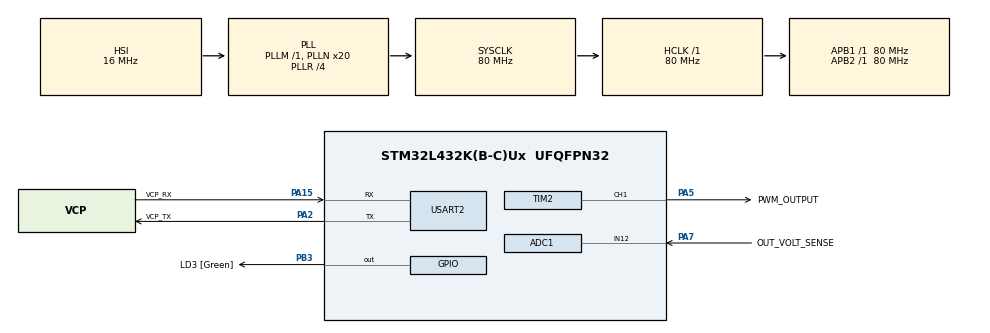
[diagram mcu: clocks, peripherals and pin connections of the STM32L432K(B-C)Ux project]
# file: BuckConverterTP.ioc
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ADC1.Channel-3\#ChannelRegularConversion=ADC_CHANNEL_12
ADC1.ClockPrescaler=ADC_CLOCK_ASYNC_DIV6
ADC1.ContinuousConvMode=ENABLE
ADC1.DMAContinuousRequests=ENABLE
ADC1.NbrOfConversionFlag=1
ADC1.OffsetNumber-3\#ChannelRegularConversion=ADC_OFFSET_NONE
ADC1.Overrun=ADC_OVR_DATA_OVERWRITTEN
ADC1.OversamplingMode=DISABLE
ADC1.Rank-3\#ChannelRegularConversion=1
ADC1.Resolution=ADC_RESOLUTION_12B
ADC1.SamplingTime-3\#ChannelRegularConversion=ADC_SAMPLETIME_640CYCLES_5
ADC1.master=1
Dma.ADC1.0.Direction=DMA_PERIPH_TO_MEMORY
Dma.ADC1.0.Instance=DMA1_Channel1
Dma.ADC1.0.MemDataAlignment=DMA_MDATAALIGN_HALFWORD
Dma.ADC1.0.MemInc=DMA_MINC_ENABLE
Dma.ADC1.0.Mode=DMA_CIRCULAR
Dma.ADC1.0.PeriphDataAlignment=DMA_PDATAALIGN_HALFWORD
Dma.ADC1.0.PeriphInc=DMA_PINC_DISABLE
Dma.ADC1.0.Priority=DMA_PRIORITY_HIGH
Dma.Request0=ADC1
Mcu.Family=STM32L4
Mcu.Name=STM32L432K(B-C)Ux
Mcu.Package=UFQFPN32
NVIC.DMA1_Channel1_IRQn=true\:0\:0\:false\:false\:true\:false\:true\:true
NVIC.PriorityGroup=NVIC_PRIORITYGROUP_4
NVIC.TIM1_BRK_TIM15_IRQn=true\:0\:0\:false\:false\:true\:true\:true\:true
NVIC.TIM1_UP_TIM16_IRQn=true\:0\:0\:false\:false\:true\:true\:true\:true
NVIC.TIM2_IRQn=true\:0\:0\:false\:false\:true\:true\:true\:true
PA0.GPIO_Label=MCO [High speed clock in]
PA0.Mode=HSE-External-Clock-Source-for-LittleOrca
PA0.Signal=RCC_CK_IN
PA13\ (JTMS-SWDIO).GPIO_Label=SWDIO
PA13\ (JTMS-SWDIO).Mode=Serial_Wire
PA13\ (JTMS-SWDIO).Signal=SYS_JTMS-SWDIO
PA14\ (JTCK-SWCLK).GPIO_Label=SWCLK
PA14\ (JTCK-SWCLK).Mode=Serial_Wire
PA14\ (JTCK-SWCLK).Signal=SYS_JTCK-SWCLK
PA15\ (JTDI).GPIO_Label=VCP_RX
PA15\ (JTDI).Mode=Asynchronous
PA15\ (JTDI).Signal=USART2_RX
PA2.GPIO_Label=VCP_TX
PA2.Mode=Asynchronous
PA2.Signal=USART2_TX
PA5.GPIO_Label=PWM_OUTPUT
PA5.GPIO_PuPd=GPIO_NOPULL
PA5.GPIO_Speed=GPIO_SPEED_FREQ_MEDIUM
PA5.Signal=S_TIM2_CH1
PA7.GPIO_Label=OUT_VOLT_SENSE
PA7.Signal=ADCx_IN12
PB3\ (JTDO-TRACESWO).GPIO_Label=LD3 [Green]
PB3\ (JTDO-TRACESWO).Signal=GPIO_Output
PC14-OSC32_IN\ (PC14).Mode=LSE-External-Oscillator
PC14-OSC32_IN\ (PC14).Signal=RCC_OSC32_IN
PC15-OSC32_OUT\ (PC15).Mode=LSE-External-Oscillator
PC15-OSC32_OUT\ (PC15).Signal=RCC_OSC32_OUT
ProjectManager.HeapSize=0x200
ProjectManager.StackSize=0x400
ProjectManager.TargetToolchain=STM32CubeIDE
RCC.ADCFreq_Value=64000000
RCC.AHBFreq_Value=80000000
RCC.APB1Freq_Value=80000000
RCC.APB1TimFreq_Value=80000000
RCC.APB2Freq_Value=80000000
RCC.APB2TimFreq_Value=80000000
RCC.CortexFreq_Value=80000000
RCC.HCLKFreq_Value=80000000
RCC.HSE_VALUE=8000000
RCC.HSI16_VALUE=16000000
RCC.HSI48_VALUE=48000000
RCC.HSI_VALUE=16000000
RCC.MSI_VALUE=4000000
RCC.PLLMUL=RCC_PLLMUL_4
RCC.PLLN=20
RCC.PLLR=RCC_PLLR_DIV4
RCC.PLLSourceVirtual=RCC_PLLSOURCE_HSI
RCC.SYSCLKFreq_VALUE=80000000
RCC.SYSCLKSource=RCC_SYSCLKSOURCE_PLLCLK
RCC.USBFreq_Value=64000000
RCC.VCOOutputFreq_Value=320000000
SH.ADCx_IN12.0=ADC1_IN12,IN12-Single-Ended
SH.S_TIM2_CH1.0=TIM2_CH1,PWM Generation1 CH1
TIM1.Channel-Output\ Compare2\ No\ Output=TIM_CHANNEL_2
TIM1.Period=1000-1
TIM1.Prescaler=16-1
TIM2.Channel-PWM\ Generation1\ CH1=TIM_CHANNEL_1
TIM2.OCMode_PWM-PWM\ Generation1\ CH1=TIM_OCMODE_PWM2
TIM2.Period=1000-1
TIM2.Prescaler=16-1
USART2.VirtualMode-Asynchronous=VM_ASYNC
VP_TIM1_VS_no_output2.Mode=Output Compare2 No Output
board=NUCLEO-L432KC

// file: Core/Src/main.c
/* USER CODE BEGIN Header */
/**
  ******************************************************************************
  * @file           : main.c
  * @brief          : Main program body
  ******************************************************************************
  * @attention
  *
  * Copyright (c) 2024 STMicroelectronics.
  * All rights reserved.
  *
  * This software is licensed under terms that can be found in the LICENSE file
  * in the root directory of this software component.
  * If no LICENSE file comes with this software, it is provided AS-IS.
  *
  ******************************************************************************
  */
/* USER CODE END Header */
#include "main.h"

/* USER CODE BEGIN Includes */
#include "BuckRegulatorMicrocontroller.h"
/* USER CODE END Includes */

ADC_HandleTypeDef hadc1;
DMA_HandleTypeDef hdma_adc1;

TIM_HandleTypeDef htim1;
TIM_HandleTypeDef htim2;

UART_HandleTypeDef huart2;

void SystemClock_Config(void);
static void MX_GPIO_Init(void);
static void MX_DMA_Init(void);
static void MX_USART2_UART_Init(void);
static void MX_ADC1_Init(void);
static void MX_TIM2_Init(void);
static void MX_TIM1_Init(void);

int main(void)
{

  /* MCU Configuration--------------------------------------------------------*/

  /* Reset of all peripherals, Initializes the Flash interface and the Systick. */
  HAL_Init();

  /* USER CODE BEGIN Init */
  BuckRegulatorMicrocontroller_initialize();
  /* USER CODE END Init */

  /* Configure the system clock */
  SystemClock_Config();

  /* Initialize all configured peripherals */
  MX_GPIO_Init();
  MX_DMA_Init();
  MX_USART2_UART_Init();
  MX_ADC1_Init();
  MX_TIM2_Init();
  MX_TIM1_Init();
  /* USER CODE BEGIN 2 */
  rtU.targetVoltage = 5.00;
  uint16_t rawAdcVal = 0;
  rtU.outputVoltage = 0.00;
  // HAL_DMA_Init(&hdma_adc1);
  HAL_TIM_PWM_Start(&htim2, TIM_CHANNEL_1);
  HAL_ADC_Start_DMA(&hadc1, &rawAdcVal, 1);
  /* USER CODE END 2 */

  /* Infinite loop */
  /* USER CODE BEGIN WHILE */
  while (1)
  {
//	  rtU.outputVoltage = rawAdcVal / 297.0; // Voltage divider ratio 20k top 6.8k bottom
//	  BuckRegulatorMicrocontroller_step();
//	  __HAL_TIM_SET_COMPARE(&htim2, TIM_CHANNEL_1, rtY.pwmPercent * 1000); // PWM gets inverted by external BJT
    /* USER CODE END WHILE */

  }
}

void SystemClock_Config(void)
{
  RCC_OscInitTypeDef RCC_OscInitStruct = {0};
  RCC_ClkInitTypeDef RCC_ClkInitStruct = {0};

  /** Configure the main internal regulator output voltage
  */
  if (HAL_PWREx_ControlVoltageScaling(PWR_REGULATOR_VOLTAGE_SCALE1) != HAL_OK)
  {
    Error_Handler();
  }

  /** Initializes the RCC Oscillators according to the specified parameters
  * in the RCC_OscInitTypeDef structure.
  */
  RCC_OscInitStruct.OscillatorType = RCC_OSCILLATORTYPE_HSI;
  RCC_OscInitStruct.HSIState = RCC_HSI_ON;
  RCC_OscInitStruct.HSICalibrationValue = RCC_HSICALIBRATION_DEFAULT;
  RCC_OscInitStruct.PLL.PLLState = RCC_PLL_ON;
  RCC_OscInitStruct.PLL.PLLSource = RCC_PLLSOURCE_HSI;
  RCC_OscInitStruct.PLL.PLLM = 1;
  RCC_OscInitStruct.PLL.PLLN = 20;
  RCC_OscInitStruct.PLL.PLLP = RCC_PLLP_DIV7;
  RCC_OscInitStruct.PLL.PLLQ = RCC_PLLQ_DIV2;
  RCC_OscInitStruct.PLL.PLLR = RCC_PLLR_DIV4;
  if (HAL_RCC_OscConfig(&RCC_OscInitStruct) != HAL_OK)
  {
    Error_Handler();
  }

  /** Initializes the CPU, AHB and APB buses clocks
  */
  RCC_ClkInitStruct.ClockType = RCC_CLOCKTYPE_HCLK|RCC_CLOCKTYPE_SYSCLK
                              |RCC_CLOCKTYPE_PCLK1|RCC_CLOCKTYPE_PCLK2;
  RCC_ClkInitStruct.SYSCLKSource = RCC_SYSCLKSOURCE_PLLCLK;
  RCC_ClkInitStruct.AHBCLKDivider = RCC_SYSCLK_DIV1;
  RCC_ClkInitStruct.APB1CLKDivider = RCC_HCLK_DIV1;
  RCC_ClkInitStruct.APB2CLKDivider = RCC_HCLK_DIV1;

  if (HAL_RCC_ClockConfig(&RCC_ClkInitStruct, FLASH_LATENCY_4) != HAL_OK)
  {
    Error_Handler();
  }
}

static void MX_ADC1_Init(void)
{

  ADC_ChannelConfTypeDef sConfig = {0};

  /** Common config
  */
  hadc1.Instance = ADC1;
  hadc1.Init.ClockPrescaler = ADC_CLOCK_ASYNC_DIV6;
  hadc1.Init.Resolution = ADC_RESOLUTION_12B;
  hadc1.Init.DataAlign = ADC_DATAALIGN_RIGHT;
  hadc1.Init.ScanConvMode = ADC_SCAN_DISABLE;
  hadc1.Init.EOCSelection = ADC_EOC_SINGLE_CONV;
  hadc1.Init.LowPowerAutoWait = DISABLE;
  hadc1.Init.ContinuousConvMode = ENABLE;
  hadc1.Init.NbrOfConversion = 1;
  hadc1.Init.DiscontinuousConvMode = DISABLE;
  hadc1.Init.ExternalTrigConv = ADC_SOFTWARE_START;
  hadc1.Init.ExternalTrigConvEdge = ADC_EXTERNALTRIGCONVEDGE_NONE;
  hadc1.Init.DMAContinuousRequests = ENABLE;
  hadc1.Init.Overrun = ADC_OVR_DATA_OVERWRITTEN;
  hadc1.Init.OversamplingMode = DISABLE;
  if (HAL_ADC_Init(&hadc1) != HAL_OK)
  {
    Error_Handler();
  }

  /** Configure Regular Channel
  */
  sConfig.Channel = ADC_CHANNEL_12;
  sConfig.Rank = ADC_REGULAR_RANK_1;
  sConfig.SamplingTime = ADC_SAMPLETIME_640CYCLES_5;
  sConfig.SingleDiff = ADC_SINGLE_ENDED;
  sConfig.OffsetNumber = ADC_OFFSET_NONE;
  sConfig.Offset = 0;
  if (HAL_ADC_ConfigChannel(&hadc1, &sConfig) != HAL_OK)
  {
    Error_Handler();
  }

}

static void MX_TIM1_Init(void)
{

  TIM_MasterConfigTypeDef sMasterConfig = {0};
  TIM_OC_InitTypeDef sConfigOC = {0};
  TIM_BreakDeadTimeConfigTypeDef sBreakDeadTimeConfig = {0};

  htim1.Instance = TIM1;
  htim1.Init.Prescaler = 16-1;
  htim1.Init.CounterMode = TIM_COUNTERMODE_UP;
  htim1.Init.Period = 1000-1;
  htim1.Init.ClockDivision = TIM_CLOCKDIVISION_DIV1;
  htim1.Init.RepetitionCounter = 0;
  htim1.Init.AutoReloadPreload = TIM_AUTORELOAD_PRELOAD_DISABLE;
  if (HAL_TIM_OC_Init(&htim1) != HAL_OK)
  {
    Error_Handler();
  }
  sMasterConfig.MasterOutputTrigger = TIM_TRGO_RESET;
  sMasterConfig.MasterOutputTrigger2 = TIM_TRGO2_RESET;
  sMasterConfig.MasterSlaveMode = TIM_MASTERSLAVEMODE_DISABLE;
  if (HAL_TIMEx_MasterConfigSynchronization(&htim1, &sMasterConfig) != HAL_OK)
  {
    Error_Handler();
  }
  sConfigOC.OCMode = TIM_OCMODE_TIMING;
  sConfigOC.Pulse = 0;
  sConfigOC.OCPolarity = TIM_OCPOLARITY_HIGH;
  sConfigOC.OCNPolarity = TIM_OCNPOLARITY_HIGH;
  sConfigOC.OCFastMode = TIM_OCFAST_DISABLE;
  sConfigOC.OCIdleState = TIM_OCIDLESTATE_RESET;
  sConfigOC.OCNIdleState = TIM_OCNIDLESTATE_RESET;
  if (HAL_TIM_OC_ConfigChannel(&htim1, &sConfigOC, TIM_CHANNEL_2) != HAL_OK)
  {
    Error_Handler();
  }
  sBreakDeadTimeConfig.OffStateRunMode = TIM_OSSR_DISABLE;
  sBreakDeadTimeConfig.OffStateIDLEMode = TIM_OSSI_DISABLE;
  sBreakDeadTimeConfig.LockLevel = TIM_LOCKLEVEL_OFF;
  sBreakDeadTimeConfig.DeadTime = 0;
  sBreakDeadTimeConfig.BreakState = TIM_BREAK_DISABLE;
  sBreakDeadTimeConfig.BreakPolarity = TIM_BREAKPOLARITY_HIGH;
  sBreakDeadTimeConfig.BreakFilter = 0;
  sBreakDeadTimeConfig.Break2State = TIM_BREAK2_DISABLE;
  sBreakDeadTimeConfig.Break2Polarity = TIM_BREAK2POLARITY_HIGH;
  sBreakDeadTimeConfig.Break2Filter = 0;
  sBreakDeadTimeConfig.AutomaticOutput = TIM_AUTOMATICOUTPUT_DISABLE;
  if (HAL_TIMEx_ConfigBreakDeadTime(&htim1, &sBreakDeadTimeConfig) != HAL_OK)
  {
    Error_Handler();
  }

}

static void MX_TIM2_Init(void)
{

  TIM_MasterConfigTypeDef sMasterConfig = {0};
  TIM_OC_InitTypeDef sConfigOC = {0};

  htim2.Instance = TIM2;
  htim2.Init.Prescaler = 16-1;
  htim2.Init.CounterMode = TIM_COUNTERMODE_UP;
  htim2.Init.Period = 1000-1;
  htim2.Init.ClockDivision = TIM_CLOCKDIVISION_DIV1;
  htim2.Init.AutoReloadPreload = TIM_AUTORELOAD_PRELOAD_DISABLE;
  if (HAL_TIM_PWM_Init(&htim2) != HAL_OK)
  {
    Error_Handler();
  }
  sMasterConfig.MasterOutputTrigger = TIM_TRGO_RESET;
  sMasterConfig.MasterSlaveMode = TIM_MASTERSLAVEMODE_DISABLE;
  if (HAL_TIMEx_MasterConfigSynchronization(&htim2, &sMasterConfig) != HAL_OK)
  {
    Error_Handler();
  }
  sConfigOC.OCMode = TIM_OCMODE_PWM2;
  sConfigOC.Pulse = 0;
  sConfigOC.OCPolarity = TIM_OCPOLARITY_HIGH;
  sConfigOC.OCFastMode = TIM_OCFAST_DISABLE;
  if (HAL_TIM_PWM_ConfigChannel(&htim2, &sConfigOC, TIM_CHANNEL_1) != HAL_OK)
  {
    Error_Handler();
  }
  HAL_TIM_MspPostInit(&htim2);

}

static void MX_USART2_UART_Init(void)
{

  huart2.Instance = USART2;
  huart2.Init.BaudRate = 115200;
  huart2.Init.WordLength = UART_WORDLENGTH_8B;
  huart2.Init.StopBits = UART_STOPBITS_1;
  huart2.Init.Parity = UART_PARITY_NONE;
  huart2.Init.Mode = UART_MODE_TX_RX;
  huart2.Init.HwFlowCtl = UART_HWCONTROL_NONE;
  huart2.Init.OverSampling = UART_OVERSAMPLING_16;
  huart2.Init.OneBitSampling = UART_ONE_BIT_SAMPLE_DISABLE;
  huart2.AdvancedInit.AdvFeatureInit = UART_ADVFEATURE_NO_INIT;
  if (HAL_UART_Init(&huart2) != HAL_OK)
  {
    Error_Handler();
  }

}

static void MX_DMA_Init(void)
{

  /* DMA controller clock enable */
  __HAL_RCC_DMA1_CLK_ENABLE();

  /* DMA interrupt init */
  /* DMA1_Channel1_IRQn interrupt configuration */
  HAL_NVIC_SetPriority(DMA1_Channel1_IRQn, 0, 0);
  HAL_NVIC_EnableIRQ(DMA1_Channel1_IRQn);

}

static void MX_GPIO_Init(void)
{
  GPIO_InitTypeDef GPIO_InitStruct = {0};

  /* GPIO Ports Clock Enable */
  __HAL_RCC_GPIOC_CLK_ENABLE();
  __HAL_RCC_GPIOA_CLK_ENABLE();
  __HAL_RCC_GPIOB_CLK_ENABLE();

  /*Configure GPIO pin Output Level */
  HAL_GPIO_WritePin(LD3_GPIO_Port, LD3_Pin, GPIO_PIN_RESET);

  /*Configure GPIO pin : LD3_Pin */
  GPIO_InitStruct.Pin = LD3_Pin;
  GPIO_InitStruct.Mode = GPIO_MODE_OUTPUT_PP;
  GPIO_InitStruct.Pull = GPIO_NOPULL;
  GPIO_InitStruct.Speed = GPIO_SPEED_FREQ_LOW;
  HAL_GPIO_Init(LD3_GPIO_Port, &GPIO_InitStruct);

}

/* USER CODE BEGIN 4 */
void HAL_TIM_PeriodElapsedCallback(TIM_HandleTypeDef* htim)
{
	// Run computations when timer period is complete
	rtU.outputVoltage = rawAdcVal / 297.0; // Voltage divider ratio 20k top 6.8k bottom
	BuckRegulatorMicrocontroller_step();
	__HAL_TIM_SET_COMPARE(&htim2, TIM_CHANNEL_1, rtY.pwmPercent * 1000); // PWM gets inverted by external BJT
}
/* USER CODE END 4 */

void Error_Handler(void)
{
  __disable_irq();
  while (1)
  {
  }
}
